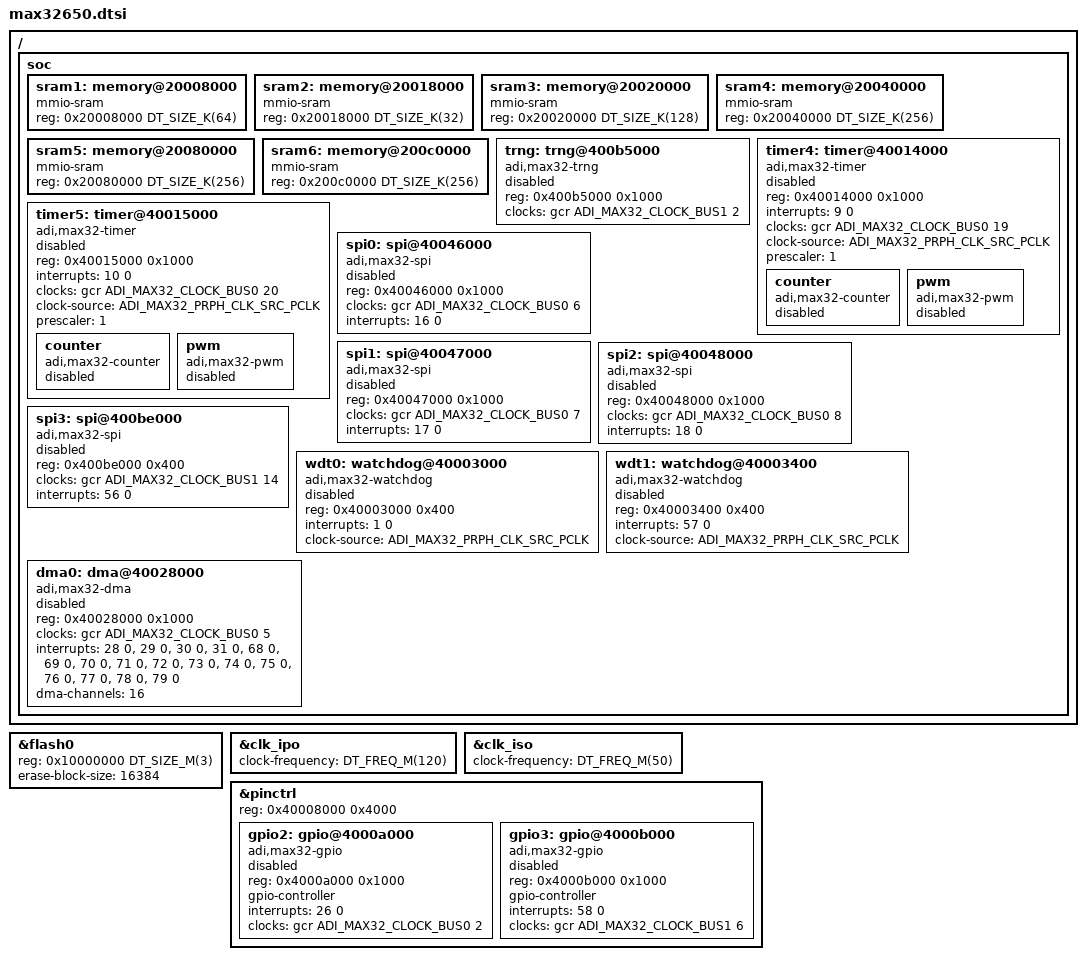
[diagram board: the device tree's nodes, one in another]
/*
 * Copyright (c) 2025 Analog Devices, Inc.
 *
 * SPDX-License-Identifier: Apache-2.0
 */

#include <arm/armv7-m.dtsi>
#include <adi/max32/max32xxx.dtsi>
#include <zephyr/dt-bindings/dma/max32650_dma.h>

&flash0 {
	reg = <0x10000000 DT_SIZE_M(3)>;
	erase-block-size = <16384>;
};

&clk_ipo {
	clock-frequency = <DT_FREQ_M(120)>;
};

&clk_iso {
	clock-frequency = <DT_FREQ_M(50)>;
};

/delete-node/ &clk_erfo;

/delete-node/ &i2c2;

/delete-node/ &trng;

/delete-node/ &wdt0;

&pinctrl {
	reg = <0x40008000 0x4000>;

	gpio2: gpio@4000a000 {
		reg = <0x4000a000 0x1000>;
		compatible = "adi,max32-gpio";
		gpio-controller;
		#gpio-cells = <2>;
		interrupts = <26 0>;
		clocks = <&gcr ADI_MAX32_CLOCK_BUS0 2>;
		status = "disabled";
	};

	gpio3: gpio@4000b000 {
		reg = <0x4000b000 0x1000>;
		compatible = "adi,max32-gpio";
		gpio-controller;
		#gpio-cells = <2>;
		interrupts = <58 0>;
		clocks = <&gcr ADI_MAX32_CLOCK_BUS1 6>;
		status = "disabled";
	};
};

/* MAX32650 extra peripherals. */
/ {
	soc {
		sram1: memory@20008000 {
			compatible = "mmio-sram";
			reg = <0x20008000 DT_SIZE_K(64)>;
		};

		sram2: memory@20018000 {
			compatible = "mmio-sram";
			reg = <0x20018000 DT_SIZE_K(32)>;
		};

		sram3: memory@20020000 {
			compatible = "mmio-sram";
			reg = <0x20020000 DT_SIZE_K(128)>;
		};

		sram4: memory@20040000 {
			compatible = "mmio-sram";
			reg = <0x20040000 DT_SIZE_K(256)>;
		};

		sram5: memory@20080000 {
			compatible = "mmio-sram";
			reg = <0x20080000 DT_SIZE_K(256)>;
		};

		sram6: memory@200c0000 {
			compatible = "mmio-sram";
			reg = <0x200c0000 DT_SIZE_K(256)>;
		};

		trng: trng@400b5000 {
			compatible = "adi,max32-trng";
			reg = <0x400b5000 0x1000>;
			clocks = <&gcr ADI_MAX32_CLOCK_BUS1 2>;
			status = "disabled";
		};

		timer4: timer@40014000 {
			compatible = "adi,max32-timer";
			reg = <0x40014000 0x1000>;
			interrupts = <9 0>;
			status = "disabled";
			clocks = <&gcr ADI_MAX32_CLOCK_BUS0 19>;
			clock-source = <ADI_MAX32_PRPH_CLK_SRC_PCLK>;
			prescaler = <1>;

			counter {
				compatible = "adi,max32-counter";
				status = "disabled";
			};

			pwm {
				compatible = "adi,max32-pwm";
				status = "disabled";
				#pwm-cells = <3>;
			};
		};

		timer5: timer@40015000 {
			compatible = "adi,max32-timer";
			reg = <0x40015000 0x1000>;
			interrupts = <10 0>;
			status = "disabled";
			clocks = <&gcr ADI_MAX32_CLOCK_BUS0 20>;
			clock-source = <ADI_MAX32_PRPH_CLK_SRC_PCLK>;
			prescaler = <1>;

			counter {
				compatible = "adi,max32-counter";
				status = "disabled";
			};

			pwm {
				compatible = "adi,max32-pwm";
				status = "disabled";
				#pwm-cells = <3>;
			};
		};

		spi0: spi@40046000 {
			compatible = "adi,max32-spi";
			reg = <0x40046000 0x1000>;
			#address-cells = <1>;
			#size-cells = <0>;
			clocks = <&gcr ADI_MAX32_CLOCK_BUS0 6>;
			interrupts = <16 0>;
			status = "disabled";
		};

		spi1: spi@40047000 {
			compatible = "adi,max32-spi";
			reg = <0x40047000 0x1000>;
			#address-cells = <1>;
			#size-cells = <0>;
			clocks = <&gcr ADI_MAX32_CLOCK_BUS0 7>;
			interrupts = <17 0>;
			status = "disabled";
		};

		spi2: spi@40048000 {
			compatible = "adi,max32-spi";
			reg = <0x40048000 0x1000>;
			#address-cells = <1>;
			#size-cells = <0>;
			clocks = <&gcr ADI_MAX32_CLOCK_BUS0 8>;
			interrupts = <18 0>;
			status = "disabled";
		};

		spi3: spi@400be000 {
			compatible = "adi,max32-spi";
			reg = <0x400be000 0x400>;
			#address-cells = <1>;
			#size-cells = <0>;
			clocks = <&gcr ADI_MAX32_CLOCK_BUS1 14>;
			interrupts = <56 0>;
			status = "disabled";
		};

		wdt0: watchdog@40003000 {
			compatible = "adi,max32-watchdog";
			reg = <0x40003000 0x400>;
			interrupts = <1 0>;
			clock-source = <ADI_MAX32_PRPH_CLK_SRC_PCLK>;
			status = "disabled";
		};

		wdt1: watchdog@40003400 {
			compatible = "adi,max32-watchdog";
			reg = <0x40003400 0x400>;
			interrupts = <57 0>;
			clock-source = <ADI_MAX32_PRPH_CLK_SRC_PCLK>;
			status = "disabled";
		};

		dma0: dma@40028000 {
			compatible = "adi,max32-dma";
			reg = <0x40028000 0x1000>;
			clocks = <&gcr ADI_MAX32_CLOCK_BUS0 5>;
			interrupts = <28 0>, <29 0>, <30 0>, <31 0>, <68 0>, <69 0>, <70 0>, <71 0>,
				     <72 0>, <73 0>, <74 0>, <75 0>, <76 0>, <77 0>, <78 0>, <79 0>;
			dma-channels = <16>;
			status = "disabled";
			#dma-cells = <2>;
		};
	};
};
